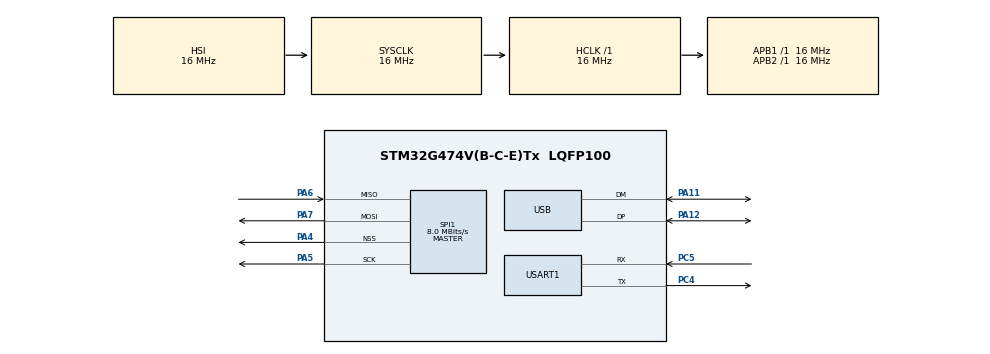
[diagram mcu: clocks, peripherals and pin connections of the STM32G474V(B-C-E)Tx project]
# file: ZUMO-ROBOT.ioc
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FREERTOS.Tasks01=defaultTask,0,128,StartDefaultTask,Default,NULL,Dynamic,NULL,NULL
Mcu.Family=STM32G4
Mcu.Name=STM32G474V(B-C-E)Tx
Mcu.Package=LQFP100
NVIC.PriorityGroup=NVIC_PRIORITYGROUP_4
NVIC.USB_LP_IRQn=true\:5\:0\:false\:false\:true\:true\:false\:true\:true
PA11.Mode=Device
PA11.Signal=USB_DM
PA12.Mode=Device
PA12.Signal=USB_DP
PA13.Mode=Serial_Wire
PA13.Signal=SYS_JTMS-SWDIO
PA14.Mode=Serial_Wire
PA14.Signal=SYS_JTCK-SWCLK
PA4.Mode=NSS_Signal_Hard_Output
PA4.Signal=SPI1_NSS
PA5.Mode=Full_Duplex_Master
PA5.Signal=SPI1_SCK
PA6.Mode=Full_Duplex_Master
PA6.Signal=SPI1_MISO
PA7.Mode=Full_Duplex_Master
PA7.Signal=SPI1_MOSI
PC14-OSC32_IN.Mode=LSE-External-Oscillator
PC14-OSC32_IN.Signal=RCC_OSC32_IN
PC15-OSC32_OUT.Mode=LSE-External-Oscillator
PC15-OSC32_OUT.Signal=RCC_OSC32_OUT
PC4.Mode=Asynchronous
PC4.Signal=USART1_TX
PC5.Mode=Asynchronous
PC5.Signal=USART1_RX
PF0-OSC_IN.Mode=HSE-External-Oscillator
PF0-OSC_IN.Signal=RCC_OSC_IN
PF1-OSC_OUT.Mode=HSE-External-Oscillator
PF1-OSC_OUT.Signal=RCC_OSC_OUT
ProjectManager.HeapSize=0x200
ProjectManager.StackSize=0x400
ProjectManager.TargetToolchain=Makefile
RCC.AHBFreq_Value=16000000
RCC.APB1Freq_Value=16000000
RCC.APB1TimFreq_Value=16000000
RCC.APB2Freq_Value=16000000
RCC.APB2TimFreq_Value=16000000
RCC.CortexFreq_Value=16000000
RCC.EXTERNAL_CLOCK_VALUE=12288000
RCC.HCLKFreq_Value=16000000
RCC.HSE_VALUE=8000000
RCC.HSI48_VALUE=48000000
RCC.HSI_VALUE=16000000
RCC.SYSCLKFreq_VALUE=16000000
RCC.USBFreq_Value=64000000
RCC.VCOOutputFreq_Value=128000000
SPI1.CalculateBaudRate=8.0 MBits/s
SPI1.DataSize=SPI_DATASIZE_8BIT
SPI1.Direction=SPI_DIRECTION_2LINES
SPI1.Mode=SPI_MODE_MASTER
SPI1.VirtualNSS=VM_NSSHARD
SPI1.VirtualType=VM_MASTER
USART1.VirtualMode-Asynchronous=VM_ASYNC
USB_DEVICE.CLASS_NAME_FS=CDC
USB_DEVICE.VirtualMode=Cdc
USB_DEVICE.VirtualModeFS=Cdc_FS
VP_FREERTOS_VS_CMSIS_V1.Mode=CMSIS_V1
VP_SYS_VS_DBSignals.Mode=DisableDeadBatterySignals
VP_USB_DEVICE_VS_USB_DEVICE_CDC_FS.Mode=CDC_FS
board=custom

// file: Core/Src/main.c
/* USER CODE BEGIN Header */
/**
 ******************************************************************************
* @file           : main.c
* @brief          : Main program body
******************************************************************************
* @attention
*
* Copyright (c) 2023 STMicroelectronics.
* All rights reserved.
*
* This software is licensed under terms that can be found in the LICENSE file
* in the root directory of this software component.
* If no LICENSE file comes with this software, it is provided AS-IS.
*
******************************************************************************
*/
/* USER CODE END Header */
#include "main.h"
#include "cmsis_os.h"
#include "usb_device.h"

SPI_HandleTypeDef hspi1;

UART_HandleTypeDef huart1;

osThreadId defaultTaskHandle;

void SystemClock_Config(void);
static void MX_GPIO_Init(void);
static void MX_USART1_UART_Init(void);
static void MX_SPI1_Init(void);
void StartDefaultTask(void const * argument);

/* USER CODE BEGIN PFP */
extern void task_zumoInit(void* params);

/* USER CODE END PFP */

int main(void)
{

  /* MCU Configuration--------------------------------------------------------*/

  /* Reset of all peripherals, Initializes the Flash interface and the Systick. */
  HAL_Init();

  /* Configure the system clock */
  SystemClock_Config();

  /* Initialize all configured peripherals */
  MX_GPIO_Init();
  MX_USART1_UART_Init();
  MX_SPI1_Init();
  MX_USB_Device_Init();

  /* Create the thread(s) */
  /* definition and creation of defaultTask */
  osThreadDef(defaultTask, StartDefaultTask, osPriorityNormal, 0, 128);
  defaultTaskHandle = osThreadCreate(osThread(defaultTask), NULL);

  /* USER CODE BEGIN RTOS_THREADS */
  /* add threads, ... */
  if (pdPASS != xTaskCreate(task_zumoInit, "Init Task", configMINIMAL_STACK_SIZE, NULL, 3, NULL)) {
    return 0;
  }
  /* USER CODE END RTOS_THREADS */

  /* Start scheduler */
  osKernelStart();

  /* We should never get here as control is now taken by the scheduler */
  /* Infinite loop */
while (1)
{

}
}

void SystemClock_Config(void)
{
  RCC_OscInitTypeDef RCC_OscInitStruct = {0};
  RCC_ClkInitTypeDef RCC_ClkInitStruct = {0};

  /** Configure the main internal regulator output voltage
  */
  HAL_PWREx_ControlVoltageScaling(PWR_REGULATOR_VOLTAGE_SCALE1);

  /** Initializes the RCC Oscillators according to the specified parameters
  * in the RCC_OscInitTypeDef structure.
  */
  RCC_OscInitStruct.OscillatorType = RCC_OSCILLATORTYPE_HSI;
  RCC_OscInitStruct.HSIState = RCC_HSI_ON;
  RCC_OscInitStruct.HSICalibrationValue = RCC_HSICALIBRATION_DEFAULT;
  RCC_OscInitStruct.PLL.PLLState = RCC_PLL_ON;
  RCC_OscInitStruct.PLL.PLLSource = RCC_PLLSOURCE_HSI;
  RCC_OscInitStruct.PLL.PLLM = RCC_PLLM_DIV1;
  RCC_OscInitStruct.PLL.PLLN = 8;
  RCC_OscInitStruct.PLL.PLLP = RCC_PLLP_DIV2;
  RCC_OscInitStruct.PLL.PLLQ = RCC_PLLQ_DIV2;
  RCC_OscInitStruct.PLL.PLLR = RCC_PLLR_DIV2;
  if (HAL_RCC_OscConfig(&RCC_OscInitStruct) != HAL_OK)
  {
    Error_Handler();
  }

  /** Initializes the CPU, AHB and APB buses clocks
  */
  RCC_ClkInitStruct.ClockType = RCC_CLOCKTYPE_HCLK|RCC_CLOCKTYPE_SYSCLK
                              |RCC_CLOCKTYPE_PCLK1|RCC_CLOCKTYPE_PCLK2;
  RCC_ClkInitStruct.SYSCLKSource = RCC_SYSCLKSOURCE_HSI;
  RCC_ClkInitStruct.AHBCLKDivider = RCC_SYSCLK_DIV1;
  RCC_ClkInitStruct.APB1CLKDivider = RCC_HCLK_DIV1;
  RCC_ClkInitStruct.APB2CLKDivider = RCC_HCLK_DIV1;

  if (HAL_RCC_ClockConfig(&RCC_ClkInitStruct, FLASH_LATENCY_0) != HAL_OK)
  {
    Error_Handler();
  }
}

static void MX_SPI1_Init(void)
{

  /* SPI1 parameter configuration*/
  hspi1.Instance = SPI1;
  hspi1.Init.Mode = SPI_MODE_MASTER;
  hspi1.Init.Direction = SPI_DIRECTION_2LINES;
  hspi1.Init.DataSize = SPI_DATASIZE_8BIT;
  hspi1.Init.CLKPolarity = SPI_POLARITY_LOW;
  hspi1.Init.CLKPhase = SPI_PHASE_1EDGE;
  hspi1.Init.NSS = SPI_NSS_HARD_OUTPUT;
  hspi1.Init.BaudRatePrescaler = SPI_BAUDRATEPRESCALER_2;
  hspi1.Init.FirstBit = SPI_FIRSTBIT_MSB;
  hspi1.Init.TIMode = SPI_TIMODE_DISABLE;
  hspi1.Init.CRCCalculation = SPI_CRCCALCULATION_DISABLE;
  hspi1.Init.CRCPolynomial = 7;
  hspi1.Init.CRCLength = SPI_CRC_LENGTH_DATASIZE;
  hspi1.Init.NSSPMode = SPI_NSS_PULSE_ENABLE;
  if (HAL_SPI_Init(&hspi1) != HAL_OK)
  {
    Error_Handler();
  }

}

static void MX_USART1_UART_Init(void)
{

  huart1.Instance = USART1;
  huart1.Init.BaudRate = 115200;
  huart1.Init.WordLength = UART_WORDLENGTH_8B;
  huart1.Init.StopBits = UART_STOPBITS_1;
  huart1.Init.Parity = UART_PARITY_NONE;
  huart1.Init.Mode = UART_MODE_TX_RX;
  huart1.Init.HwFlowCtl = UART_HWCONTROL_NONE;
  huart1.Init.OverSampling = UART_OVERSAMPLING_16;
  huart1.Init.OneBitSampling = UART_ONE_BIT_SAMPLE_DISABLE;
  huart1.Init.ClockPrescaler = UART_PRESCALER_DIV1;
  huart1.AdvancedInit.AdvFeatureInit = UART_ADVFEATURE_NO_INIT;
  if (HAL_UART_Init(&huart1) != HAL_OK)
  {
    Error_Handler();
  }
  if (HAL_UARTEx_SetTxFifoThreshold(&huart1, UART_TXFIFO_THRESHOLD_1_8) != HAL_OK)
  {
    Error_Handler();
  }
  if (HAL_UARTEx_SetRxFifoThreshold(&huart1, UART_RXFIFO_THRESHOLD_1_8) != HAL_OK)
  {
    Error_Handler();
  }
  if (HAL_UARTEx_DisableFifoMode(&huart1) != HAL_OK)
  {
    Error_Handler();
  }

}

static void MX_GPIO_Init(void)
{

  /* GPIO Ports Clock Enable */
  __HAL_RCC_GPIOC_CLK_ENABLE();
  __HAL_RCC_GPIOF_CLK_ENABLE();
  __HAL_RCC_GPIOA_CLK_ENABLE();

}

void StartDefaultTask(void const * argument)
{
  for(;;)
  {
    osDelay(1);
  }
}

void Error_Handler(void)
{
__disable_irq();
while (1)
{
}
}
